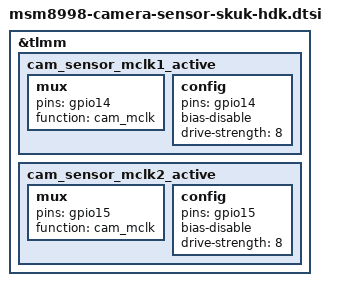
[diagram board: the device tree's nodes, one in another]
/*
 * Copyright (c) 2017, The Linux Foundation. All rights reserved.
 *
 * This program is free software; you can redistribute it and/or modify
 * it under the terms of the GNU General Public License version 2 and
 * only version 2 as published by the Free Software Foundation.
 *
 * This program is distributed in the hope that it will be useful,
 * but WITHOUT ANY WARRANTY; without even the implied warranty of
 * MERCHANTABILITY or FITNESS FOR A PARTICULAR PURPOSE.  See the
 * GNU General Public License for more details.
 */

#include "msm8998-camera-sensor-skuk-evt3.dtsi"

&tlmm{
	cam_sensor_mclk1_active: cam_sensor_mclk1_active {
		/* MCLK1 */
		mux {
			/* CLK, DATA */
			pins = "gpio14";
			function = "cam_mclk";
		};

		config {
			pins = "gpio14";
			bias-disable; /* No PULL */
			drive-strength = <8>; /* 2 MA */
		};
	};

	cam_sensor_mclk2_active: cam_sensor_mclk2_active {
		/* MCLK1 */
		mux {
			/* CLK, DATA */
			pins = "gpio15";
			function = "cam_mclk";
		};

		config {
			pins = "gpio15";
			bias-disable; /* No PULL */
			drive-strength = <8>; /* 2 MA */
		};
	};
};
